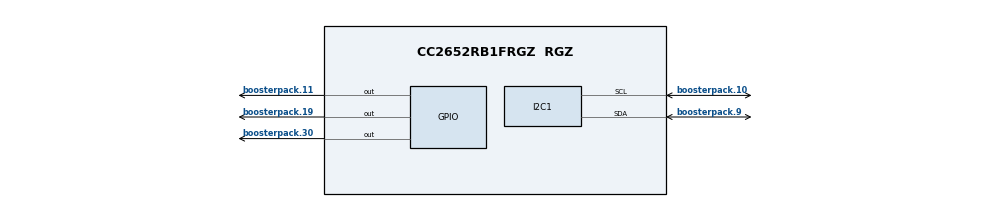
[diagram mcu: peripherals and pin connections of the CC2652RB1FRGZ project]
/**
 * @cliArgs --board "/ti/boards/LP_CC2652RB" --device "CC2652RB1FRGZ" --part "Default" --package "RGZ" --rtos "tirtos7" --product "simplelink_cc13xx_cc26xx_sdk@8.30.01.01"
 * @versions {"tool":"1.21.1+3772"}
 */

/**
 * Import the modules used in this configuration.
 */
const ble          = scripting.addModule("/ti/ble5stack/ble");
const CCFG         = scripting.addModule("/ti/devices/CCFG");
const rfdesign     = scripting.addModule("/ti/devices/radioconfig/rfdesign");
const Display      = scripting.addModule("/ti/display/Display");
const Display1     = Display.addInstance();
const AESCCM       = scripting.addModule("/ti/drivers/AESCCM");
const AESCCM1      = AESCCM.addInstance();
const AESCTRDRBG   = scripting.addModule("/ti/drivers/AESCTRDRBG");
const AESCTRDRBG1  = AESCTRDRBG.addInstance();
const AESECB       = scripting.addModule("/ti/drivers/AESECB");
const AESECB1      = AESECB.addInstance();
const ECDH         = scripting.addModule("/ti/drivers/ECDH");
const ECDH1        = ECDH.addInstance();
const GPIO         = scripting.addModule("/ti/drivers/GPIO");
const GPIO1        = GPIO.addInstance();
const GPIO2        = GPIO.addInstance();
const GPIO3        = GPIO.addInstance();
const GPIO4        = GPIO.addInstance();
const GPIO5        = GPIO.addInstance();
const I2C          = scripting.addModule("/ti/drivers/I2C", {}, false);
const I2C1         = I2C.addInstance();
const NVS          = scripting.addModule("/ti/drivers/NVS");
const NVS1         = NVS.addInstance();
const Power        = scripting.addModule("/ti/drivers/Power");
const RF           = scripting.addModule("/ti/drivers/RF");
const TRNG         = scripting.addModule("/ti/drivers/TRNG");
const TRNG1        = TRNG.addInstance();
const UART2        = scripting.addModule("/ti/drivers/UART2");
const UART21       = UART2.addInstance();
const Settings     = scripting.addModule("/ti/posix/tirtos/Settings");
const BIOS         = scripting.addModule("/ti/sysbios/BIOS");
const GateMutexPri = scripting.addModule("/ti/sysbios/gates/GateMutexPri");
const HeapCallback = scripting.addModule("/ti/sysbios/heaps/HeapCallback");
const Event        = scripting.addModule("/ti/sysbios/knl/Event");
const Idle         = scripting.addModule("/ti/sysbios/knl/Idle", {}, false);
const Idle2        = Idle.addInstance();
const Mailbox      = scripting.addModule("/ti/sysbios/knl/Mailbox");
const Error        = scripting.addModule("/ti/sysbios/runtime/Error");
const SysCallback  = scripting.addModule("/ti/sysbios/runtime/SysCallback");
const Timestamp    = scripting.addModule("/ti/sysbios/runtime/Timestamp");

/**
 * Write custom configuration values to the imported modules.
 */
ble.lockProject                                           = true;
ble.deviceName                                            = "BAWSimplePeri";
ble.disableDisplayModule                                  = true;
ble.maxPDUNum                                             = 6;
ble.maxNumPrepareWrites                                   = 6;
ble.maxConnNum                                            = 1;
ble.maxPDUSize                                            = 255;
ble.tbmActiveItemsOnly                                    = false;
ble.uartLog                                               = true;
ble.radioConfig.codeExportConfig.$name                    = "ti_devices_radioconfig_code_export_param0";
ble.connUpdateParamsPeripheral.$name                      = "ti_ble5stack_general_ble_conn_update_params0";
ble.connUpdateParamsPeripheral.paramUpdateDelay           = 0;
ble.connUpdateParamsPeripheral.reqMinConnInt              = 7.5;
ble.connUpdateParamsPeripheral.reqMaxConnInt              = 20;
ble.advSet1.$name                                         = "ti_ble5stack_broadcaster_advertisement_set0";
ble.advSet1.advParam1.$name                               = "ti_ble5stack_broadcaster_advertisement_params0";
ble.advSet1.advParam1.primIntMin                          = 20;
ble.advSet1.advParam1.primIntMax                          = 20;
ble.advSet1.advData1.$name                                = "ti_ble5stack_broadcaster_advertisement_data0";
ble.advSet1.advData1.GAP_ADTYPE_FLAGS                     = true;
ble.advSet1.advData1.advertisingFlags                     = ["GAP_ADTYPE_FLAGS_BREDR_NOT_SUPPORTED","GAP_ADTYPE_FLAGS_GENERAL"];
ble.advSet1.advData1.GAP_ADTYPE_16BIT_MORE                = true;
ble.advSet1.advData1.numOfUUIDs16More                     = 1;
ble.advSet1.advData1.UUID016More                          = 0xFFF0;
ble.advSet1.advData1.shortenedLocalName                   = "SP";
ble.advSet1.advData1.minConnInterval                      = 7.5;
ble.advSet1.advData1.maxConnInterval                      = 7.5;
ble.advSet1.advData1.GAP_ADTYPE_LOCAL_NAME_COMPLETE       = true;
ble.advSet1.scanRes1.$name                                = "ti_ble5stack_broadcaster_advertisement_data1";
ble.advSet1.scanRes1.GAP_ADTYPE_LOCAL_NAME_COMPLETE       = true;
ble.advSet1.scanRes1.GAP_ADTYPE_SLAVE_CONN_INTERVAL_RANGE = true;
ble.advSet1.scanRes1.GAP_ADTYPE_POWER_LEVEL               = true;
ble.advSet1.scanRes1.minConnInterval                      = 7.5;
ble.advSet1.scanRes1.maxConnInterval                      = 7.5;
ble.advSet2.$name                                         = "ti_ble5stack_broadcaster_advertisement_set1";
ble.advSet2.advParam2.$name                               = "ti_ble5stack_broadcaster_advertisement_params1";
ble.advSet2.advParam2.advType                             = "extended";
ble.advSet2.advParam2.primPhy                             = "GAP_ADV_PRIM_PHY_1_MBPS";
ble.advSet2.advParam2.secPhy                              = "GAP_ADV_SEC_PHY_2_MBPS";
ble.advSet2.advParam2.primIntMin                          = 20;
ble.advSet2.advParam2.primIntMax                          = 20;
ble.advSet2.advData2.$name                                = "ti_ble5stack_broadcaster_advertisement_data2";
ble.advSet2.advData2.minConnInterval                      = 7.5;
ble.advSet2.advData2.maxConnInterval                      = 7.5;
ble.advSet2.advData2.GAP_ADTYPE_LOCAL_NAME_SHORT          = true;
ble.advSet2.advData2.shortenedLocalName                   = "SP";
ble.advSet2.advData2.GAP_ADTYPE_16BIT_MORE                = true;
ble.advSet2.advData2.numOfUUIDs16More                     = 1;
ble.advSet2.advData2.UUID016More                          = 0xFFF0;
ble.advSet2.scanRes2.$name                                = "ti_ble5stack_broadcaster_advertisement_data3";
scripting.suppress("If scanning or connection initiation on the 2M PHY is used, the max number of bonds that can be saved in NV is 21\\.", ble.advSet2.advParam2, "secPhy");

CCFG.enableBootloader         = true;
CCFG.enableBootloaderBackdoor = true;
CCFG.dioBootloaderBackdoor    = 13;
CCFG.levelBootloaderBackdoor  = "Active low";
CCFG.ccfgTemplate.$name       = "ti_devices_CCFG_CCFGCC26XXTemplate0";

Display1.$name                    = "CONFIG_Display_0";
Display1.$hardware                = system.deviceData.board.components.XDS110UART;
Display1.enableANSI               = true;
Display1.uartBufferSize           = 128;
Display1.uart.$name               = "CONFIG_DISPLAY_UART";
Display1.uart.txRingBufferSize    = 64;
Display1.uart.txPinInstance.$name = "CONFIG_GPIO_UART_TX";
Display1.uart.rxPinInstance.$name = "CONFIG_GPIO_UART_RX";

AESCCM1.$name = "CONFIG_AESCCM0";

AESCTRDRBG1.$name = "CONFIG_AESCTRDRBG_0";

AESECB1.$name = "CONFIG_AESECB0";

ECDH1.$name = "CONFIG_ECDH0";

GPIO1.$hardware = system.deviceData.board.components["BTN-1"];
GPIO1.$name     = "CONFIG_GPIO_BTN1";

GPIO2.$hardware = system.deviceData.board.components["BTN-2"];
GPIO2.$name     = "CONFIG_GPIO_BTN2";

GPIO3.mode            = "Output";
GPIO3.$name           = "CONFIG_GPIO_DEBUG_BLE";
GPIO3.gpioPin.$assign = "boosterpack.30";

GPIO4.$name            = "CONFIG_GPIO_INT_ISM";
GPIO4.interruptTrigger = "Rising Edge";
GPIO4.gpioPin.$assign  = "boosterpack.11";

GPIO5.$name            = "CONFIG_GPIO_INT_H3L";
GPIO5.interruptTrigger = "Rising Edge";
GPIO5.gpioPin.$assign  = "boosterpack.19";

I2C1.$name              = "CONFIG_I2C_0";
I2C1.maxBitRate         = 3400000;
I2C1.i2c.$assign        = "I2C0";
I2C1.i2c.sdaPin.$assign = "boosterpack.9";
I2C1.i2c.sclPin.$assign = "boosterpack.10";

NVS1.$name                    = "CONFIG_NVSINTERNAL";
NVS1.internalFlash.$name      = "ti_drivers_nvs_NVSCC26XX0";
NVS1.internalFlash.regionBase = 0x48000;
NVS1.internalFlash.regionSize = 0x4000;

Power.calibrateRCOSC_HF = false;

RF.xoscNeeded = false;

TRNG1.$name = "CONFIG_TRNG_0";

UART2.loggingEnabled         = true;
UART2.LogModule.enable_DEBUG = true;
UART2.LogModule.enable_INFO  = true;

UART21.$name            = "CONFIG_UART2_0";
UART21.txRingBufferSize = 64;

const LogSinkBuf       = scripting.addModule("/ti/log/LogSinkBuf", {}, false);
const LogSinkBuf1      = LogSinkBuf.addInstance({}, false);
LogSinkBuf1.$name      = "CONFIG_ti_log_LogSinkBuf_0";
UART2.LogModule.logger = LogSinkBuf1;

BIOS.assertsEnabled   = false;
BIOS.rtsGateType      = "BIOS_GateMutexPri";
BIOS.heapSize         = 0x00000000;
BIOS.heapType         = "HeapCallback";
BIOS.heapTrackEnabled = true;

HeapCallback.initFxn           = "osalHeapInitFxn";
HeapCallback.allocInstFxn      = "osalHeapAllocFxn";
HeapCallback.freeInstFxn       = "osalHeapFreeFxn";
HeapCallback.getStatsInstFxn   = "osalHeapGetStatsFxn";
HeapCallback.isBlockingInstFxn = "osalHeapIsBlockingFxn";

const Clock       = scripting.addModule("/ti/sysbios/knl/Clock", {}, false);
Clock.tickPeriod  = 10;
Clock.swiPriority = 5;

const Timer = scripting.addModule("/ti/sysbios/family/arm/cc26xx/Timer", {}, false);

Idle2.$name   = "powerIdle";
Idle2.idleFxn = "Power_idleFunc";

const Semaphore            = scripting.addModule("/ti/sysbios/knl/Semaphore", {}, false);
Semaphore.supportsPriority = false;

const Swi         = scripting.addModule("/ti/sysbios/knl/Swi", {}, false);
Swi.numPriorities = 6;

const Task             = scripting.addModule("/ti/sysbios/knl/Task", {}, false);
Task.defaultStackSize  = 512;
Task.idleTaskStackSize = 768;
Task.numPriorities     = 6;

Error.policy       = "Error_SPIN";
Error.printDetails = false;

const System           = scripting.addModule("/ti/sysbios/runtime/System", {}, false);
System.abortFxn        = "System_abortSpin";
System.exitFxn         = "System_exitSpin";
System.extendedFormats = "%f";
System.supportModule   = "SysCallback";

/**
 * Pinmux solution for unlocked pins/peripherals. This ensures that minor changes to the automatic solver in a future
 * version of the tool will not impact the pinmux you originally saw.  These lines can be completely deleted in order to
 * re-solve from scratch.
 */
Display1.uart.uart.$suggestSolution       = "UART0";
Display1.uart.uart.txPin.$suggestSolution = "boosterpack.4";
Display1.uart.uart.rxPin.$suggestSolution = "boosterpack.3";
GPIO1.gpioPin.$suggestSolution            = "boosterpack.13";
GPIO2.gpioPin.$suggestSolution            = "boosterpack.12";
UART21.uart.$suggestSolution              = "UART1";
UART21.uart.txPin.$suggestSolution        = "boosterpack.32";
UART21.uart.rxPin.$suggestSolution        = "boosterpack.29";
Timer.rtc.$suggestSolution                = "RTC0";
